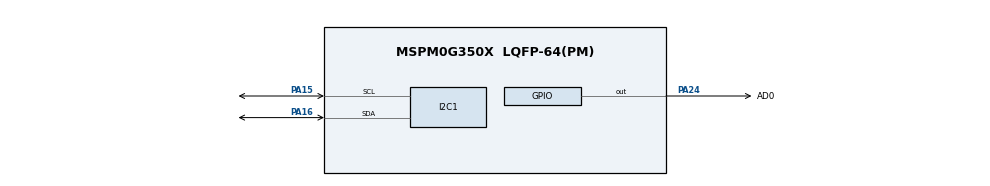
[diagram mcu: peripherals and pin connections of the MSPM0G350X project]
/**
 * @cliArgs --device "MSPM0G350X" --part "Default" --package "LQFP-64(PM)" --product "mspm0_sdk@2.10.00.04"
 * @versions {"tool":"1.26.2+4477"}
 */

/**
 * Import the modules used in this configuration.
 */
const SYSCTL = scripting.addModule("/ti/driverlib/SYSCTL");
const ADC12  = scripting.addModule("/ti/driverlib/ADC12", {}, false);
const ADC121 = ADC12.addInstance();
const I2C    = scripting.addModule("/ti/driverlib/I2C", {}, false);
const I2C1   = I2C.addInstance();
const GPIO   = scripting.addModule("/ti/driverlib/GPIO", {}, false);
const GPIO_Grey  = GPIO.addInstance();
const GPIO_DAT   = GPIO.addInstance();
const GPIO_BLK   = GPIO.addInstance();
const GPIO_CS    = GPIO.addInstance();
const GPIO_DC    = GPIO.addInstance();
const GPIO_RES   = GPIO.addInstance();
const GPIO_MOSI  = GPIO.addInstance();
const GPIO_SCLK  = GPIO.addInstance();
const TIMER  = scripting.addModule("/ti/driverlib/TIMER", {}, false);
const TIMER1 = TIMER.addInstance();
const Board  = scripting.addModule("/ti/driverlib/Board", {}, false);

/**
 * Write custom configuration values to the imported modules.
 */

/* ---- 时钟树: 32 MHz CPUCLK ---- */
const divider7       = system.clockTree["PLL_PDIV"];
divider7.divideValue = 2;

const divider9       = system.clockTree["UDIV"];
divider9.divideValue = 2;

const multiplier2         = system.clockTree["PLL_QDIV"];
multiplier2.multiplyValue = 5;

const mux8       = system.clockTree["HSCLKMUX"];
mux8.inputSelect = "HSCLKMUX_SYSPLL2X";

/* ---- ADC12: 灰度传感器 (PA27, 单通道, 软件触发, 轮询模式) ---- */
ADC121.$name                             = "Grey_ADC";
ADC121.peripheral.$assign                = "ADC0";
ADC121.peripheral.adcPin0.$assign        = "PA27";
ADC121.sampClkSrc                        = "DL_ADC12_CLOCK_ULPCLK";
ADC121.sampClkDiv                        = "DL_ADC12_CLOCK_DIVIDE_8";
ADC121.powerDownMode                     = "DL_ADC12_POWER_DOWN_MODE_MANUAL";
ADC121.sampleTime0                       = "125 us";

/* ---- GPIO: 灰度传感器 CLK (PA24, 输出) ---- */
GPIO_Grey.$name                         = "Grey";
GPIO_Grey.associatedPins.create(1);
GPIO_Grey.associatedPins[0].$name       = "AD0";
GPIO_Grey.associatedPins[0].pin.$assign = "PA24";

/* ---- GPIO: 灰度传感器 DAT (PA25, 输入上拉) ---- */
GPIO_DAT.$name                               = "DAT";
GPIO_DAT.port                                = "PORTA";
GPIO_DAT.associatedPins[0].$name             = "PIN_25";
GPIO_DAT.associatedPins[0].direction         = "INPUT";
GPIO_DAT.associatedPins[0].internalResistor  = "NONE";
GPIO_DAT.associatedPins[0].assignedPin       = "25";

/* ---- GPIO: LCD 背光 BLK (PB19, 低电平点亮) ---- */
GPIO_BLK.$name                         = "BLK";
GPIO_BLK.port                          = "PORTB";
GPIO_BLK.associatedPins[0].$name       = "PIN_19";
GPIO_BLK.associatedPins[0].assignedPin = "19";

/* ---- GPIO: LCD 片选 CS (PA23) ---- */
GPIO_CS.$name                          = "CS";
GPIO_CS.port                           = "PORTA";
GPIO_CS.associatedPins[0].$name        = "PIN_23";
GPIO_CS.associatedPins[0].assignedPin  = "23";

/* ---- GPIO: LCD 数据/命令 DC (PB24) ---- */
GPIO_DC.$name                          = "DC";
GPIO_DC.port                           = "PORTB";
GPIO_DC.associatedPins[0].$name        = "PIN_24";
GPIO_DC.associatedPins[0].assignedPin  = "24";

/* ---- GPIO: LCD 复位 RES (PB20) ---- */
GPIO_RES.$name                         = "RES";
GPIO_RES.port                          = "PORTB";
GPIO_RES.associatedPins[0].$name       = "PIN_20";
GPIO_RES.associatedPins[0].assignedPin = "20";

/* ---- GPIO: LCD 数据 MOSI (PA28) ---- */
GPIO_MOSI.$name                        = "MOSI";
GPIO_MOSI.port                         = "PORTA";
GPIO_MOSI.associatedPins[0].$name      = "PIN_28";
GPIO_MOSI.associatedPins[0].assignedPin = "28";

/* ---- GPIO: LCD 时钟 SCLK (PA31) ---- */
GPIO_SCLK.$name                        = "SCLK";
GPIO_SCLK.port                         = "PORTA";
GPIO_SCLK.associatedPins[0].$name      = "PIN_31";
GPIO_SCLK.associatedPins[0].assignedPin = "31";

/* ---- I2C: MPU6050 传感器 (Fast Mode 400kHz) ---- */
I2C1.$name                           = "I2C_MPU6050";
I2C1.basicEnableController           = true;
I2C1.basicControllerStandardBusSpeed = "Fast";
I2C1.peripheral.sclPin.$assign       = "PA15";
I2C1.peripheral.sdaPin.$assign       = "PA16";

/* ---- TIMER: TIMG0 1ms 周期中断 ---- */
TIMER1.$name              = "TIMER_0";
TIMER1.timerClkSrc        = "BUSCLK";
TIMER1.timerPeriod        = "1 ms";
TIMER1.interrupts         = ["ZERO"];
TIMER1.timerClkPrescale   = 8;
TIMER1.peripheral.$assign = "TIMG0";

SYSCTL.forceDefaultClkConfig = true;

/**
 * Pinmux solution for unlocked pins/peripherals.
 */
GPIO_BLK.associatedPins[0].pin.$suggestSolution   = "PB19";
GPIO_CS.associatedPins[0].pin.$suggestSolution    = "PA23";
GPIO_DC.associatedPins[0].pin.$suggestSolution    = "PB24";
GPIO_RES.associatedPins[0].pin.$suggestSolution   = "PB20";
GPIO_MOSI.associatedPins[0].pin.$suggestSolution  = "PA28";
GPIO_SCLK.associatedPins[0].pin.$suggestSolution  = "PA31";
GPIO_DAT.associatedPins[0].pin.$suggestSolution     = "PA25";
I2C1.peripheral.sclPin.$suggestSolution             = "PA15";
I2C1.peripheral.sdaPin.$suggestSolution             = "PA16";
Board.peripheral.$suggestSolution                 = "DEBUGSS";
Board.peripheral.swclkPin.$suggestSolution        = "PA20";
Board.peripheral.swdioPin.$suggestSolution        = "PA19";
